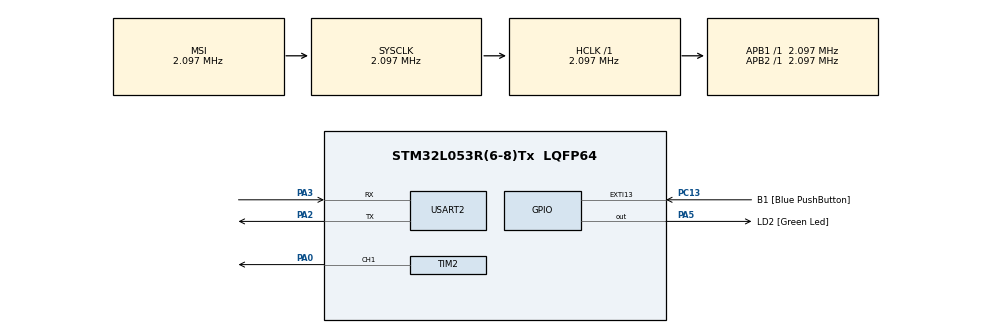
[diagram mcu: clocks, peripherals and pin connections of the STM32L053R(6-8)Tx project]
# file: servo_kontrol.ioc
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Mcu.Family=STM32L0
Mcu.Name=STM32L053R(6-8)Tx
Mcu.Package=LQFP64
NVIC.TIM2_IRQn=true\:0\:0\:false\:false\:true\:true\:true\:true
PA0.Signal=S_TIM2_CH1
PA13.GPIO_Label=TMS
PA13.Mode=Serial_Wire
PA13.Signal=SYS_SWDIO
PA14.GPIO_Label=TCK
PA14.Mode=Serial_Wire
PA14.Signal=SYS_SWCLK
PA2.GPIO_ModeDefaultPP=GPIO_MODE_AF_PP
PA2.GPIO_PuPd=GPIO_NOPULL
PA2.GPIO_Speed=GPIO_SPEED_FREQ_VERY_HIGH
PA2.Mode=Asynchronous
PA2.Signal=USART2_TX
PA3.GPIO_ModeDefaultPP=GPIO_MODE_AF_PP
PA3.GPIO_PuPd=GPIO_NOPULL
PA3.GPIO_Speed=GPIO_SPEED_FREQ_VERY_HIGH
PA3.Mode=Asynchronous
PA3.Signal=USART2_RX
PA5.GPIO_Label=LD2 [Green Led]
PA5.Signal=GPIO_Output
PC13.GPIO_Label=B1 [Blue PushButton]
PC13.GPIO_ModeDefaultEXTI=GPIO_MODE_IT_FALLING
PC13.Signal=GPXTI13
PC14-OSC32_IN.Signal=RCC_OSC32_IN
PC15-OSC32_OUT.Signal=RCC_OSC32_OUT
PH0-OSC_IN.Mode=HSE-External-Oscillator
PH0-OSC_IN.Signal=RCC_OSC_IN
PH1-OSC_OUT.Mode=HSE-External-Oscillator
PH1-OSC_OUT.Signal=RCC_OSC_OUT
ProjectManager.HeapSize=0x200
ProjectManager.StackSize=0x400
ProjectManager.TargetToolchain=MDK-ARM V5.32
RCC.ADCFreq_Value=16000000
RCC.AHBFreq_Value=2097000
RCC.APB1Freq_Value=2097000
RCC.APB1TimFreq_Value=2097000
RCC.APB2Freq_Value=2097000
RCC.APB2TimFreq_Value=2097000
RCC.HCLKFreq_Value=2097000
RCC.HSE_VALUE=8000000
RCC.HSI16_VALUE=16000000
RCC.HSI48_VALUE=48000000
RCC.HSI_VALUE=16000000
RCC.LSE_VALUE=32768
RCC.MSI_VALUE=2097000
RCC.PLLMUL=RCC_PLLMUL_8
RCC.PLLSourceVirtual=RCC_PLLSOURCE_HSE
RCC.SYSCLKFreq_VALUE=2097000
RCC.VCOOutputFreq_Value=64000000
SH.S_TIM2_CH1.0=TIM2_CH1,PWM Generation1 CH1
TIM2.Channel-PWM\ Generation1\ CH1=TIM_CHANNEL_1
TIM2.Period=999
TIM2.Prescaler=41
TIM2.Pulse-PWM\ Generation1\ CH1=0
USART2.VirtualMode-Asynchronous=VM_ASYNC
VP_TIM2_VS_ClockSourceINT.Mode=Internal
board=NUCLEO-L053R8

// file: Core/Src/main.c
/* USER CODE BEGIN Header */
/**
  ******************************************************************************
  * @file           : main.c
  * @brief          : Main program body
  ******************************************************************************
  * @attention
  *
  * Copyright (c) 2022 STMicroelectronics.
  * All rights reserved.
  *
  * This software is licensed under terms that can be found in the LICENSE file
  * in the root directory of this software component.
  * If no LICENSE file comes with this software, it is provided AS-IS.
  *
  ******************************************************************************
  */
/* USER CODE END Header */
#include "main.h"

TIM_HandleTypeDef htim2;

UART_HandleTypeDef huart2;

void SystemClock_Config(void);
static void MX_GPIO_Init(void);
static void MX_TIM2_Init(void);
static void MX_USART2_UART_Init(void);

int main(void)
{

  /* MCU Configuration--------------------------------------------------------*/

  /* Reset of all peripherals, Initializes the Flash interface and the Systick. */
  HAL_Init();

  /* Configure the system clock */
  SystemClock_Config();

  /* Initialize all configured peripherals */
  MX_GPIO_Init();
  MX_TIM2_Init();
  MX_USART2_UART_Init();
  /* USER CODE BEGIN 2 */
HAL_TIM_PWM_Start(&htim2, TIM_CHANNEL_1);

  /* USER CODE END 2 */

  /* Infinite loop */
  /* USER CODE BEGIN WHILE */
  while (1)
  {
		if(HAL_GPIO_ReadPin(GPIOC, GPIO_PIN_13) == 0)
			{
				htim2.Instance -> CCR1=30;  //SAAT YÖNÜ 12
				HAL_Delay(1000);
				htim2.Instance -> CCR1=75;  //SAAT YÖNÜ 9
				HAL_Delay(1000);
				htim2.Instance -> CCR1=120; //SAAT YÖNÜ 6
				HAL_Delay(1000);
				htim2.Instance -> CCR1=30;  //SAAT YÖNÜ 12
				HAL_Delay(1000);
		  }

    /* USER CODE END WHILE */

  }
}

void SystemClock_Config(void)
{
  RCC_OscInitTypeDef RCC_OscInitStruct = {0};
  RCC_ClkInitTypeDef RCC_ClkInitStruct = {0};
  RCC_PeriphCLKInitTypeDef PeriphClkInit = {0};

  /** Configure the main internal regulator output voltage
  */
  __HAL_PWR_VOLTAGESCALING_CONFIG(PWR_REGULATOR_VOLTAGE_SCALE1);

  /** Initializes the RCC Oscillators according to the specified parameters
  * in the RCC_OscInitTypeDef structure.
  */
  RCC_OscInitStruct.OscillatorType = RCC_OSCILLATORTYPE_MSI;
  RCC_OscInitStruct.MSIState = RCC_MSI_ON;
  RCC_OscInitStruct.MSICalibrationValue = 0;
  RCC_OscInitStruct.MSIClockRange = RCC_MSIRANGE_5;
  RCC_OscInitStruct.PLL.PLLState = RCC_PLL_NONE;
  if (HAL_RCC_OscConfig(&RCC_OscInitStruct) != HAL_OK)
  {
    Error_Handler();
  }

  /** Initializes the CPU, AHB and APB buses clocks
  */
  RCC_ClkInitStruct.ClockType = RCC_CLOCKTYPE_HCLK|RCC_CLOCKTYPE_SYSCLK
                              |RCC_CLOCKTYPE_PCLK1|RCC_CLOCKTYPE_PCLK2;
  RCC_ClkInitStruct.SYSCLKSource = RCC_SYSCLKSOURCE_MSI;
  RCC_ClkInitStruct.AHBCLKDivider = RCC_SYSCLK_DIV1;
  RCC_ClkInitStruct.APB1CLKDivider = RCC_HCLK_DIV1;
  RCC_ClkInitStruct.APB2CLKDivider = RCC_HCLK_DIV1;

  if (HAL_RCC_ClockConfig(&RCC_ClkInitStruct, FLASH_LATENCY_0) != HAL_OK)
  {
    Error_Handler();
  }
  PeriphClkInit.PeriphClockSelection = RCC_PERIPHCLK_USART2;
  PeriphClkInit.Usart2ClockSelection = RCC_USART2CLKSOURCE_PCLK1;
  if (HAL_RCCEx_PeriphCLKConfig(&PeriphClkInit) != HAL_OK)
  {
    Error_Handler();
  }
}

static void MX_TIM2_Init(void)
{

  TIM_ClockConfigTypeDef sClockSourceConfig = {0};
  TIM_MasterConfigTypeDef sMasterConfig = {0};
  TIM_OC_InitTypeDef sConfigOC = {0};

  htim2.Instance = TIM2;
  htim2.Init.Prescaler = 41;
  htim2.Init.CounterMode = TIM_COUNTERMODE_UP;
  htim2.Init.Period = 999;
  htim2.Init.ClockDivision = TIM_CLOCKDIVISION_DIV1;
  htim2.Init.AutoReloadPreload = TIM_AUTORELOAD_PRELOAD_DISABLE;
  if (HAL_TIM_Base_Init(&htim2) != HAL_OK)
  {
    Error_Handler();
  }
  sClockSourceConfig.ClockSource = TIM_CLOCKSOURCE_INTERNAL;
  if (HAL_TIM_ConfigClockSource(&htim2, &sClockSourceConfig) != HAL_OK)
  {
    Error_Handler();
  }
  if (HAL_TIM_PWM_Init(&htim2) != HAL_OK)
  {
    Error_Handler();
  }
  sMasterConfig.MasterOutputTrigger = TIM_TRGO_RESET;
  sMasterConfig.MasterSlaveMode = TIM_MASTERSLAVEMODE_DISABLE;
  if (HAL_TIMEx_MasterConfigSynchronization(&htim2, &sMasterConfig) != HAL_OK)
  {
    Error_Handler();
  }
  sConfigOC.OCMode = TIM_OCMODE_PWM1;
  sConfigOC.Pulse = 0;
  sConfigOC.OCPolarity = TIM_OCPOLARITY_HIGH;
  sConfigOC.OCFastMode = TIM_OCFAST_DISABLE;
  if (HAL_TIM_PWM_ConfigChannel(&htim2, &sConfigOC, TIM_CHANNEL_1) != HAL_OK)
  {
    Error_Handler();
  }
  HAL_TIM_MspPostInit(&htim2);

}

static void MX_USART2_UART_Init(void)
{

  huart2.Instance = USART2;
  huart2.Init.BaudRate = 115200;
  huart2.Init.WordLength = UART_WORDLENGTH_8B;
  huart2.Init.StopBits = UART_STOPBITS_1;
  huart2.Init.Parity = UART_PARITY_NONE;
  huart2.Init.Mode = UART_MODE_TX_RX;
  huart2.Init.HwFlowCtl = UART_HWCONTROL_NONE;
  huart2.Init.OverSampling = UART_OVERSAMPLING_16;
  huart2.Init.OneBitSampling = UART_ONE_BIT_SAMPLE_DISABLE;
  huart2.AdvancedInit.AdvFeatureInit = UART_ADVFEATURE_NO_INIT;
  if (HAL_UART_Init(&huart2) != HAL_OK)
  {
    Error_Handler();
  }

}

static void MX_GPIO_Init(void)
{
  GPIO_InitTypeDef GPIO_InitStruct = {0};

  /* GPIO Ports Clock Enable */
  __HAL_RCC_GPIOC_CLK_ENABLE();
  __HAL_RCC_GPIOH_CLK_ENABLE();
  __HAL_RCC_GPIOA_CLK_ENABLE();

  /*Configure GPIO pin Output Level */
  HAL_GPIO_WritePin(LD2_GPIO_Port, LD2_Pin, GPIO_PIN_RESET);

  /*Configure GPIO pin : B1_Pin */
  GPIO_InitStruct.Pin = B1_Pin;
  GPIO_InitStruct.Mode = GPIO_MODE_IT_FALLING;
  GPIO_InitStruct.Pull = GPIO_NOPULL;
  HAL_GPIO_Init(B1_GPIO_Port, &GPIO_InitStruct);

  /*Configure GPIO pin : LD2_Pin */
  GPIO_InitStruct.Pin = LD2_Pin;
  GPIO_InitStruct.Mode = GPIO_MODE_OUTPUT_PP;
  GPIO_InitStruct.Pull = GPIO_NOPULL;
  GPIO_InitStruct.Speed = GPIO_SPEED_FREQ_LOW;
  HAL_GPIO_Init(LD2_GPIO_Port, &GPIO_InitStruct);

}

void Error_Handler(void)
{
  __disable_irq();
  while (1)
  {
  }
}
